VERSION ""

NS_ :

BS_:

BU_: Vector__XXX

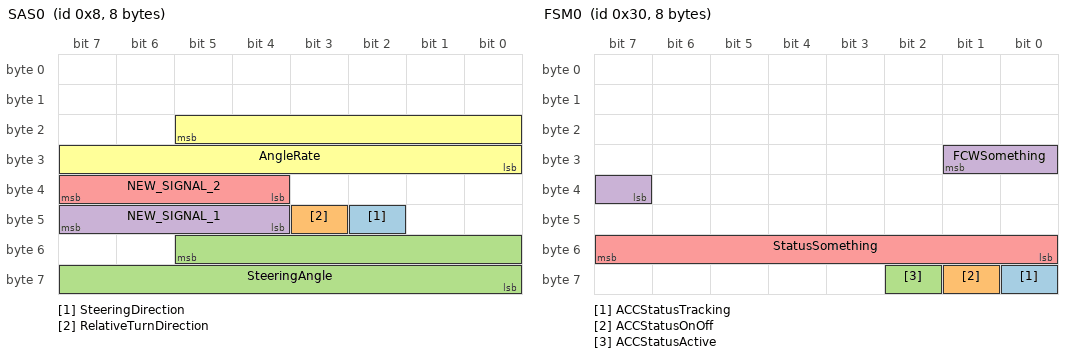
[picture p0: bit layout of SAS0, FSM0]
BO_ 8 SAS0: 8 Vector__XXX
SG_ SteeringDirection : 42|1@0+ (1,0) [0|1] "" Vector__XXX
SG_ RelativeTurnDirection : 43|1@0+ (1,0) [0|1] "" Vector__XXX
SG_ SteeringAngle : 53|14@0+ (0.04395,0) [0|720.03285] "degrees" Vector__XXX
SG_ NEW_SIGNAL_1 : 47|4@0+ (1,0) [0|15] "" Vector__XXX
SG_ NEW_SIGNAL_2 : 39|4@0+ (1,0) [0|15] "" Vector__XXX
SG_ AngleRate : 21|14@0+ (0.075,0) [0|1228.725] "deg/S" Vector__XXX

BO_ 16 CCButtons: 8 Vector__XXX
SG_ byte0 : 7|8@0+ (1,0) [0|255] "" Vector__XXX
SG_ byte1 : 15|8@0+ (1,0) [0|255] "" Vector__XXX
SG_ byte2 : 23|8@0+ (1,0) [0|255] "" Vector__XXX
SG_ byte3 : 31|8@0+ (1,0) [0|255] "" Vector__XXX
SG_ byte4 : 39|8@0+ (1,0) [0|255] "" Vector__XXX
SG_ byte6 : 55|5@0+ (1,0) [0|31] "" Vector__XXX
SG_ B7b0 : 56|1@0+ (1,0) [0|1] "" Vector__XXX
SG_ B7b1 : 57|1@0+ (1,0) [0|1] "" Vector__XXX
SG_ B7b6 : 62|1@0+ (1,0) [0|1] "" Vector__XXX
SG_ ACCOnOffBtn : 58|1@0+ (1,0) [0|1] "" Vector__XXX
SG_ ACCSetBtn : 63|1@0+ (1,0) [0|1] "" Vector__XXX
SG_ ACCStopBtn : 60|1@0+ (1,0) [0|1] "" Vector__XXX
SG_ ACCResumeBtn : 61|1@0+ (1,0) [0|1] "" Vector__XXX
SG_ ACCMinusBtn : 48|1@0+ (1,0) [0|1] "" Vector__XXX
SG_ TimeGapIncreaseBtn : 49|1@0+ (1,0) [0|1] "" Vector__XXX
SG_ TimeGapDecreaseBtn : 50|1@0+ (1,0) [0|1] "" Vector__XXX
SG_ byte5 : 47|8@0+ (1,0) [0|255] "" Vector__XXX
SG_ B7b3 : 59|1@0+ (1,0) [0|1] "" Vector__XXX

BO_ 48 FSM0: 8 Vector__XXX
SG_ ACCStatusTracking : 56|1@0+ (1,0) [0|1] "" Vector__XXX
SG_ ACCStatusOnOff : 57|1@0+ (1,0) [0|1] "" Vector__XXX
SG_ ACCStatusActive : 58|1@0+ (1,0) [0|1] "" Vector__XXX
SG_ FCWSomething : 25|3@0+ (1,0) [0|3] "" Vector__XXX
SG_ StatusSomething : 55|8@0+ (1,0) [0|255] "" Vector__XXX

BO_ 64 TCM0: 8 Vector__XXX
SG_ RPMSomething : 42|11@0+ (1,0) [0|2047] "" Vector__XXX
SG_ GearShifter : 46|2@0+ (1,0) [0|3] "" Vector__XXX

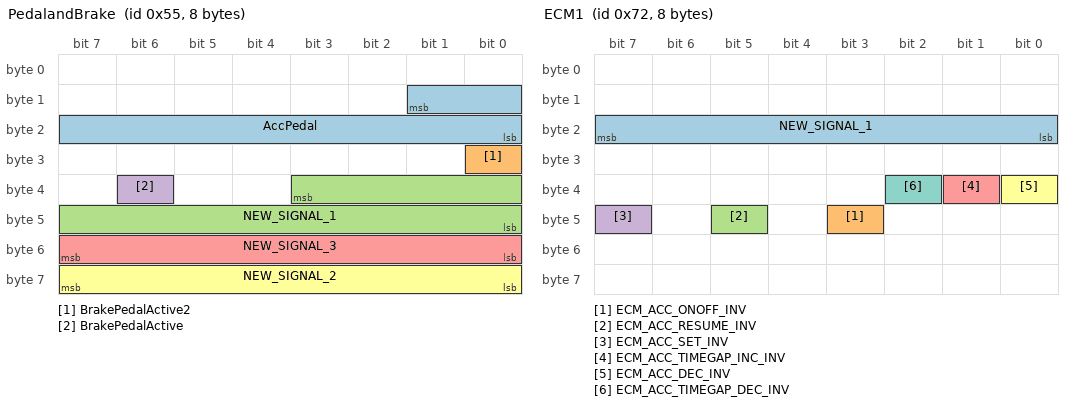
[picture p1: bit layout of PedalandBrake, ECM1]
BO_ 85 PedalandBrake: 8 Vector__XXX
SG_ AccPedal : 9|10@0+ (0.1,0) [0|102.3] "%" Vector__XXX
SG_ BrakePedalActive2 : 24|1@0+ (1,0) [0|1] "" Vector__XXX
SG_ NEW_SIGNAL_1 : 35|12@0+ (1,0) [0|4095] "" Vector__XXX
SG_ BrakePedalActive : 38|1@0+ (1,0) [0|1] "" Vector__XXX
SG_ NEW_SIGNAL_3 : 55|8@0+ (1,0) [0|255] "" Vector__XXX
SG_ NEW_SIGNAL_2 : 63|8@0+ (1,0) [0|255] "" Vector__XXX

BO_ 101 EngineInfo: 8 Vector__XXX
SG_ NEW_SIGNAL_1 : 17|10@0+ (1,-512) [0|511] "" Vector__XXX
SG_ EngineSpeed : 52|13@0+ (1,0) [0|1023] "" Vector__XXX

BO_ 112 NEW_MSG_4: 8 Vector__XXX
SG_ NEW_SIGNAL_1 : 39|8@0+ (1,0) [0|255] "" Vector__XXX

BO_ 114 ECM1: 8 Vector__XXX
SG_ NEW_SIGNAL_1 : 23|8@0+ (1,0) [0|255] "" Vector__XXX
SG_ ECM_ACC_ONOFF_INV : 43|1@0+ (1,0) [0|1] "" Vector__XXX
SG_ ECM_ACC_RESUME_INV : 45|1@0+ (1,0) [0|1] "" Vector__XXX
SG_ ECM_ACC_SET_INV : 47|1@0+ (1,0) [0|1] "" Vector__XXX
SG_ ECM_ACC_TIMEGAP_INC_INV : 33|1@0+ (1,0) [0|1] "" Vector__XXX
SG_ ECM_ACC_DEC_INV : 32|1@0+ (1,0) [0|1] "" Vector__XXX
SG_ ECM_ACC_TIMEGAP_DEC_INV : 34|1@0+ (1,0) [0|1] "" Vector__XXX

BO_ 117 ECM1_2: 8 Vector__XXX

BO_ 128 NEW_MSG_5: 8 Vector__XXX
SG_ NEW_SIGNAL_2 : 26|11@0+ (1,0) [0|2047] "" Vector__XXX
SG_ NEW_SIGNAL_1 : 52|13@0+ (1,0) [0|8191] "" Vector__XXX

BO_ 176 ECM2: 8 Vector__XXX
SG_ NEW_SIGNAL_1 : 50|11@0+ (1,0) [0|2047] "" Vector__XXX
SG_ NEW_SIGNAL_2 : 47|8@0+ (1,0) [0|63] "" Vector__XXX

BO_ 192 Gear: 8 Vector__XXX
SG_ TransmissionGear : 36|3@0+ (1,1) [1|7] "" Vector__XXX

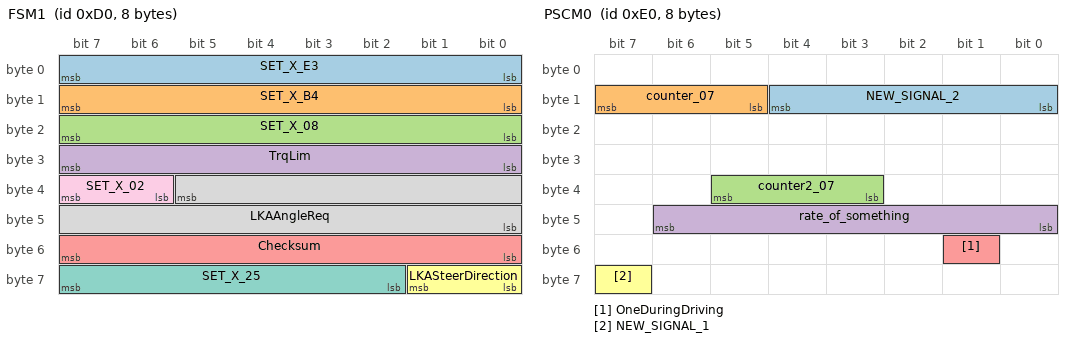
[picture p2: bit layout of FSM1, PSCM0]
BO_ 208 FSM1: 8 Vector__XXX
SG_ SET_X_E3 : 7|8@0+ (1,0) [0|255] "" Vector__XXX
SG_ SET_X_B4 : 15|8@0+ (1,0) [0|255] "" Vector__XXX
SG_ SET_X_08 : 23|8@0+ (1,0) [0|255] "" Vector__XXX
SG_ TrqLim : 31|8@0+ (1,-128) [0|127] "" Vector__XXX
SG_ Checksum : 55|8@0+ (1,0) [0|255] "" Vector__XXX
SG_ LKASteerDirection : 57|2@0+ (1,0) [0|2] "" Vector__XXX
SG_ SET_X_25 : 63|6@0+ (1,0) [0|63] "" Vector__XXX
SG_ LKAAngleReq : 37|14@0+ (0.04395,-360.0384) [-360.0384|359.99445] "degrees" Vector__XXX
SG_ SET_X_02 : 39|2@0+ (1,0) [0|3] "" Vector__XXX

BO_ 224 PSCM0: 8 Vector__XXX
SG_ NEW_SIGNAL_2 : 12|5@0+ (1,0) [0|31] "" Vector__XXX
SG_ counter_07 : 15|3@0+ (1,0) [0|7] "" Vector__XXX
SG_ counter2_07 : 37|3@0+ (1,0) [0|7] "" Vector__XXX
SG_ rate_of_something : 46|7@0+ (1,0) [0|62] "" Vector__XXX
SG_ OneDuringDriving : 49|1@0+ (1,0) [0|1] "" Vector__XXX
SG_ NEW_SIGNAL_1 : 63|1@0+ (1,0) [0|1] "" Vector__XXX

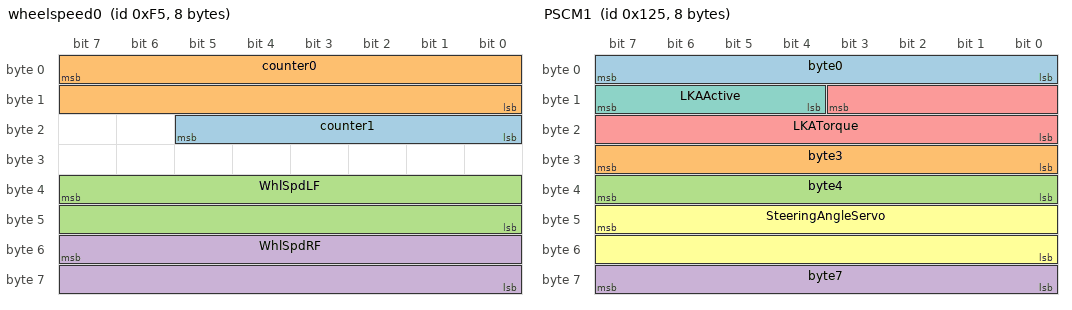
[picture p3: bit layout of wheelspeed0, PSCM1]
BO_ 245 wheelspeed0: 8 Vector__XXX
SG_ counter1 : 21|6@0+ (1,0) [0|63] "" Vector__XXX
SG_ counter0 : 7|16@0+ (1,0) [0|65535] "" Vector__XXX
SG_ WhlSpdLF : 39|16@0+ (1,0) [0|65535] "" Vector__XXX
SG_ WhlSpdRF : 55|16@0+ (1,0) [0|65535] "" Vector__XXX

BO_ 272 SpeedSignal0: 8 Vector__XXX
SG_ VehicleSpeedSignal : 55|16@0+ (0.01,0) [0|655.35] "" Vector__XXX

BO_ 288 wheel_speed1: 8 Vector__XXX
SG_ WhlSpdLR : 39|16@0+ (1,0) [0|65535] "" Vector__XXX
SG_ WhlSpdRR : 55|16@0+ (1,0) [0|65535] "" Vector__XXX

BO_ 293 PSCM1: 8 Vector__XXX
SG_ byte0 : 7|8@0+ (1,0) [0|255] "" Vector__XXX
SG_ byte3 : 31|8@0+ (1,0) [0|255] "" Vector__XXX
SG_ byte4 : 39|8@0+ (1,0) [0|255] "" Vector__XXX
SG_ byte7 : 63|8@0+ (1,0) [0|255] "" Vector__XXX
SG_ LKATorque : 11|12@0+ (1,-2000) [0|2095] "" Vector__XXX
SG_ SteeringAngleServo : 47|16@0+ (0.04395,-1440.1536) [0|1440.10965] "deg" Vector__XXX
SG_ LKAActive : 15|4@0+ (1,0) [0|15] "" Vector__XXX

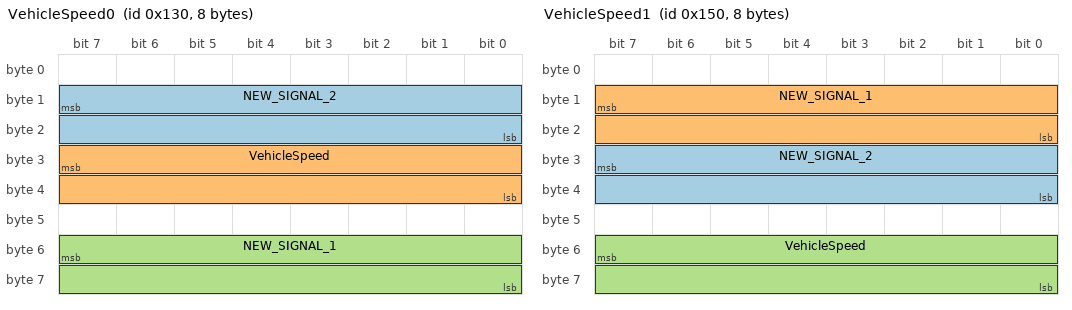
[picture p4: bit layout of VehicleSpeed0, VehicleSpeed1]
BO_ 304 VehicleSpeed0: 8 Vector__XXX
SG_ NEW_SIGNAL_2 : 15|16@0+ (1,0) [0|65535] "" Vector__XXX
SG_ VehicleSpeed : 31|16@0+ (0.01,0) [0|655.35] "km/h" Vector__XXX
SG_ NEW_SIGNAL_1 : 55|16@0+ (1,0) [0|65535] "" Vector__XXX

BO_ 325 ECM3: 8 Vector__XXX

BO_ 336 VehicleSpeed1: 8 Vector__XXX
SG_ NEW_SIGNAL_2 : 31|16@0+ (1,0) [0|65535] "" Vector__XXX
SG_ NEW_SIGNAL_1 : 15|16@0+ (1,0) [0|65535] "" Vector__XXX
SG_ VehicleSpeed : 55|16@0+ (0.01,0) [0|655.35] "" Vector__XXX

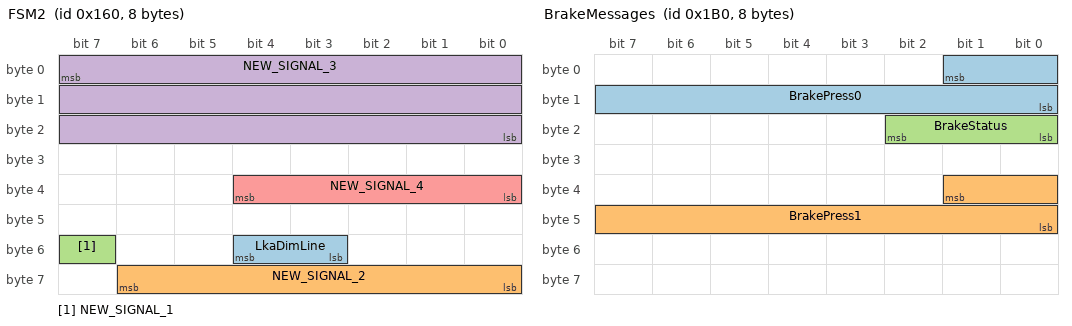
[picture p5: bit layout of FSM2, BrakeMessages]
BO_ 352 FSM2: 8 Vector__XXX
SG_ LkaDimLine : 51|2@1+ (1,0) [0|3] "" Vector__XXX
SG_ NEW_SIGNAL_2 : 56|7@1+ (1,0) [0|127] "" Vector__XXX
SG_ NEW_SIGNAL_1 : 55|1@0+ (1,0) [0|1] "" Vector__XXX
SG_ NEW_SIGNAL_3 : 7|24@0+ (1,0) [0|16777215] "" Vector__XXX
SG_ NEW_SIGNAL_4 : 36|5@0+ (1,0) [0|31] "" Vector__XXX

BO_ 432 BrakeMessages: 8 Vector__XXX
SG_ BrakePress0 : 1|10@0+ (1,0) [0|1023] "" Vector__XXX
SG_ BrakePress1 : 33|10@0+ (1,0) [0|1023] "" Vector__XXX
SG_ BrakeStatus : 18|3@0+ (1,0) [0|7] "" Vector__XXX

BO_ 464 DIM0: 8 Vector__XXX

BO_ 480 BCM0: 8 Vector__XXX

BO_ 528 CEM0: 8 Vector__XXX

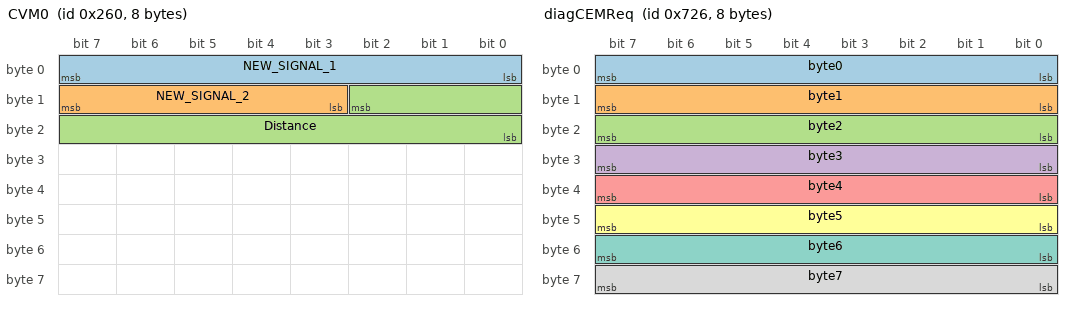
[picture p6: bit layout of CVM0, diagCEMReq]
BO_ 608 CVM0: 8 Vector__XXX
SG_ NEW_SIGNAL_1 : 7|8@0+ (1,0) [0|255] "" Vector__XXX
SG_ NEW_SIGNAL_2 : 15|5@0+ (1,0) [0|31] "" Vector__XXX
SG_ Distance : 10|11@0+ (1,0) [0|2047] "" Vector__XXX

BO_ 624 FSM3: 8 Vector__XXX
SG_ NEW_SIGNAL_1 : 23|8@0+ (1,0) [0|255] "" Vector__XXX

BO_ 640 FSM4: 8 Vector__XXX
SG_ SpeedTarget : 47|8@0+ (1,0) [0|255] "" Vector__XXX
SG_ NEW_SIGNAL_1 : 49|10@0+ (1,0) [0|255] "" Vector__XXX

BO_ 648 SRS0: 8 Vector__XXX

BO_ 652 ECM4: 8 Vector__XXX

BO_ 656 ECM5: 8 Vector__XXX

BO_ 657 ECM6: 8 Vector__XXX

BO_ 681 MiscCarInfo: 8 Vector__XXX
SG_ TurnSignal : 1|2@0+ (1,0) [0|3] "" Vector__XXX
SG_ HighBeamOn : 52|1@0+ (1,0) [0|1] "" Vector__XXX

BO_ 693 ECM7: 8 Vector__XXX

BO_ 709 ACC: 8 Vector__XXX
SG_ SpeedTargetACC : 0|9@0+ (0.5,0) [0|255.5] "" Vector__XXX

BO_ 853 FSM5: 8 Vector__XXX
SG_ TargetSpeedOdo : 23|8@0+ (1,0) [0|63] "kph" Vector__XXX
SG_ SpeedSign : 36|5@0+ (5,0) [0|32] "" Vector__XXX
SG_ TextUnderSign : 37|1@0+ (1,0) [0|1] "" Vector__XXX
SG_ NEW_SIGNAL_6 : 39|3@0+ (1,0) [0|3] "" Vector__XXX
SG_ NEW_SIGNAL_5 : 47|8@0+ (1,0) [0|255] "" Vector__XXX
SG_ NEW_SIGNAL_3 : 31|8@0+ (1,0) [0|255] "" Vector__XXX
SG_ LaneMarkingsOdo : 15|4@0+ (1,0) [0|7] "" Vector__XXX
SG_ NEW_SIGNAL_2 : 11|4@0+ (1,0) [0|15] "" Vector__XXX
SG_ NEW_SIGNAL_1 : 7|8@0+ (1,0) [0|255] "" Vector__XXX
SG_ NEW_SIGNAL_4 : 55|16@0+ (1,0) [0|65535] "" Vector__XXX

BO_ 864 CEM1: 8 Vector__XXX

BO_ 912 DIM1: 8 Vector__XXX

BO_ 968 SRS1: 8 Vector__XXX
SG_ PassengerSeatBelt : 22|1@0+ (1,0) [0|1] "" Vector__XXX
SG_ DriverSeatBelt : 19|1@0+ (1,0) [0|1] "" Vector__XXX

BO_ 1029 CEMBCM0: 8 Vector__XXX

BO_ 1344 NEW_MSG_1: 8 Vector__XXX
SG_ NEW_SIGNAL_1 : 4|13@0+ (1,0) [0|8191] "" Vector__XXX

BO_ 1830 diagCEMReq: 8 Vector__XXX
SG_ byte0 : 7|8@0+ (1,0) [0|255] "" Vector__XXX
SG_ byte1 : 15|8@0+ (1,0) [0|255] "" Vector__XXX
SG_ byte2 : 23|8@0+ (1,0) [0|255] "" Vector__XXX
SG_ byte3 : 31|8@0+ (1,0) [0|255] "" Vector__XXX
SG_ byte4 : 39|8@0+ (1,0) [0|255] "" Vector__XXX
SG_ byte5 : 47|8@0+ (1,0) [0|255] "" Vector__XXX
SG_ byte6 : 55|8@0+ (1,0) [0|255] "" Vector__XXX
SG_ byte7 : 63|8@0+ (1,0) [0|255] "" Vector__XXX

BO_ 1838 diagCEMResp: 8 Vector__XXX
SG_ byte03 : 7|32@0+ (1,0) [0|4294967295] "" Vector__XXX
SG_ byte47 : 39|32@0+ (1,0) [0|4294967295] "" Vector__XXX

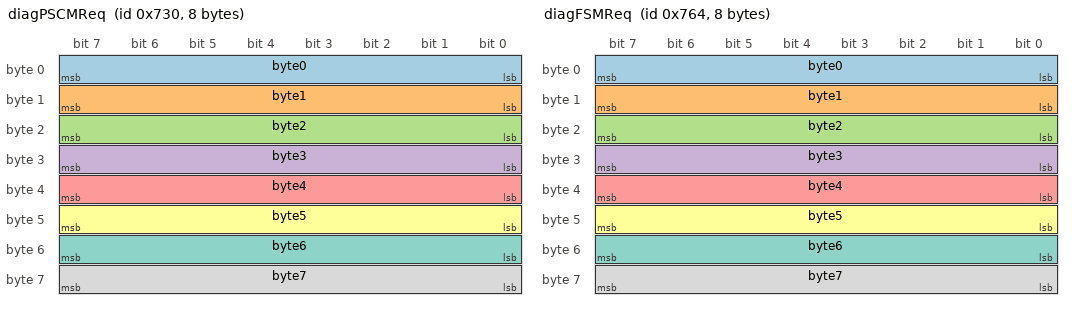
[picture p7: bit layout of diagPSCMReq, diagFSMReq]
BO_ 1840 diagPSCMReq: 8 Vector__XXX
SG_ byte0 : 7|8@0+ (1,0) [0|255] "" Vector__XXX
SG_ byte1 : 15|8@0+ (1,0) [0|255] "" Vector__XXX
SG_ byte2 : 23|8@0+ (1,0) [0|255] "" Vector__XXX
SG_ byte3 : 31|8@0+ (1,0) [0|255] "" Vector__XXX
SG_ byte4 : 39|8@0+ (1,0) [0|255] "" Vector__XXX
SG_ byte5 : 47|8@0+ (1,0) [0|255] "" Vector__XXX
SG_ byte6 : 55|8@0+ (1,0) [0|255] "" Vector__XXX
SG_ byte7 : 63|8@0+ (1,0) [0|255] "" Vector__XXX

BO_ 1848 diagPSCMResp: 8 Vector__XXX
SG_ byte03 : 7|32@0+ (1,0) [0|4294967295] "" Vector__XXX
SG_ byte47 : 39|32@0+ (1,0) [0|4294967295] "" Vector__XXX

BO_ 1892 diagFSMReq: 8 Vector__XXX
SG_ byte0 : 7|8@0+ (1,0) [0|255] "" Vector__XXX
SG_ byte1 : 15|8@0+ (1,0) [0|255] "" Vector__XXX
SG_ byte2 : 23|8@0+ (1,0) [0|255] "" Vector__XXX
SG_ byte3 : 31|8@0+ (1,0) [0|255] "" Vector__XXX
SG_ byte4 : 39|8@0+ (1,0) [0|255] "" Vector__XXX
SG_ byte5 : 47|8@0+ (1,0) [0|255] "" Vector__XXX
SG_ byte6 : 55|8@0+ (1,0) [0|255] "" Vector__XXX
SG_ byte7 : 63|8@0+ (1,0) [0|255] "" Vector__XXX

BO_ 1900 diagFSMResp: 8 Vector__XXX
SG_ byte03 : 7|32@0+ (1,0) [0|4294967295] "" Vector__XXX
SG_ byte47 : 39|32@0+ (1,0) [0|4294967295] "" Vector__XXX

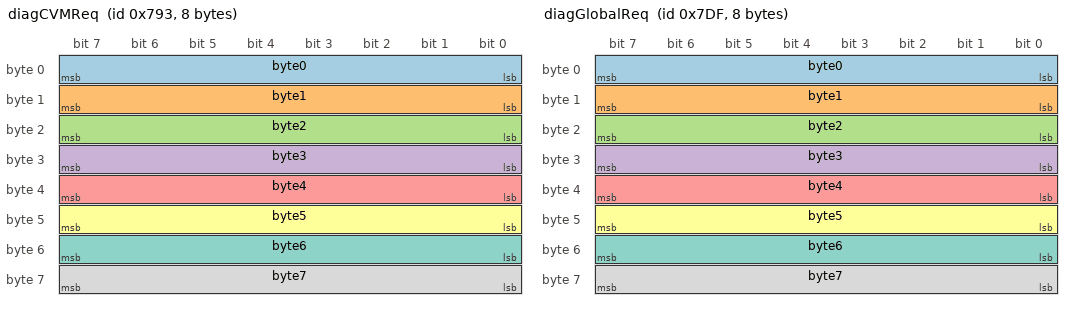
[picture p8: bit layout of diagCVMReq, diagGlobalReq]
BO_ 1939 diagCVMReq: 8 Vector__XXX
SG_ byte0 : 7|8@0+ (1,0) [0|255] "" Vector__XXX
SG_ byte1 : 15|8@0+ (1,0) [0|255] "" Vector__XXX
SG_ byte2 : 23|8@0+ (1,0) [0|255] "" Vector__XXX
SG_ byte3 : 31|8@0+ (1,0) [0|255] "" Vector__XXX
SG_ byte4 : 39|8@0+ (1,0) [0|255] "" Vector__XXX
SG_ byte5 : 47|8@0+ (1,0) [0|255] "" Vector__XXX
SG_ byte6 : 55|8@0+ (1,0) [0|255] "" Vector__XXX
SG_ byte7 : 63|8@0+ (1,0) [0|255] "" Vector__XXX

BO_ 1947 diagCVMResp: 8 Vector__XXX
SG_ byte03 : 7|32@0+ (1,0) [0|4294967295] "" Vector__XXX
SG_ byte47 : 39|32@0+ (1,0) [0|4294967295] "" Vector__XXX

BO_ 2015 diagGlobalReq: 8 Vector__XXX
SG_ byte0 : 7|8@0+ (1,0) [0|255] "" Vector__XXX
SG_ byte1 : 15|8@0+ (1,0) [0|255] "" Vector__XXX
SG_ byte2 : 23|8@0+ (1,0) [0|255] "" Vector__XXX
SG_ byte3 : 31|8@0+ (1,0) [0|255] "" Vector__XXX
SG_ byte4 : 39|8@0+ (1,0) [0|255] "" Vector__XXX
SG_ byte5 : 47|8@0+ (1,0) [0|255] "" Vector__XXX
SG_ byte6 : 55|8@0+ (1,0) [0|255] "" Vector__XXX
SG_ byte7 : 63|8@0+ (1,0) [0|255] "" Vector__XXX

CM_ SG_ 8 SteeringDirection "1=Right turn, 0=Left turn. Steering wheel pointing left or right from center (0 deg).";
CM_ SG_ 8 RelativeTurnDirection "1=Right turn, 0=Left turn. Steering wheel currently turning the way.";
CM_ SG_ 16 ACCOnOffBtn "Cruise control on/off button pressed";
CM_ SG_ 16 ACCSetBtn "Acc Set button (+) pressed";
CM_ SG_ 16 ACCStopBtn "ACC Stop button pressed";
CM_ SG_ 16 ACCResumeBtn "ACC Resume button pressed";
CM_ SG_ 16 ACCMinusBtn "ACC Minus (-) button pressed";
CM_ SG_ 16 TimeGapIncreaseBtn "Increase the time gap on ACC";
CM_ SG_ 16 TimeGapDecreaseBtn "Decrease the time gap on ACC";
CM_ SG_ 48 ACCStatusTracking "ACC Tracking vehicle, distance control.";
CM_ SG_ 48 ACCStatusOnOff "Turns one after pressing on/off button on steering wheeel";
CM_ SG_ 48 ACCStatusActive "ACC Active";
CM_ SG_ 48 FCWSomething "All bit set during fcw";
CM_ SG_ 48 StatusSomething "Some status changes when zeroing DTCs";
CM_ SG_ 64 RPMSomething "TransmissionOutput?";
CM_ SG_ 64 GearShifter "P=0, R=1, N=2, D=3";
CM_ SG_ 85 BrakePedalActive2 "Active during braking";
CM_ SG_ 85 NEW_SIGNAL_1 "Not yet figured out.";
CM_ SG_ 85 BrakePedalActive "Brake pedal pushed";
CM_ SG_ 101 NEW_SIGNAL_1 "Rate of something?";
CM_ SG_ 114 NEW_SIGNAL_1 "Jumped from 0 -> 120 during start. Makes triangle from time to time";
CM_ SG_ 192 TransmissionGear "0 = 1st gear, 1= 2nd gear...";
CM_ SG_ 208 TrqLim "Used in checksum calculation, Limit directional torque based on the number.";
CM_ SG_ 208 Checksum "Checksum calculated as a one-complement addition of LKAAngleRequest+LKADirection+Unkown, Zeros used to pad missing bits.";
CM_ SG_ 208 SET_X_02 "Bit 0 = Vibrate steering wheel., Bit 1 = Heartbeat";
CM_ SG_ 224 rate_of_something "Seems to be some kind of torque rather than rate.";
CM_ SG_ 224 OneDuringDriving "Set to 1 when vehicle is rolling.";
CM_ SG_ 245 counter0 "Speed based counter";
CM_ SG_ 245 WhlSpdLF "Wheel speed left front";
CM_ SG_ 245 WhlSpdRF "Wheel speed right front";
CM_ SG_ 272 VehicleSpeedSignal "km/h";
CM_ SG_ 288 WhlSpdLR "Wheel speed left rear";
CM_ SG_ 288 WhlSpdRR "Wheel speed right rear";
CM_ SG_ 293 byte7 "Bit0=0 when gearshift in park, else 1";
CM_ SG_ 293 LKAActive "Bit0=0 when gear in park otherwise =1, Bit1=1 when LKA Active, 0 when not active. Bit2=? Bit3=?";
CM_ SG_ 352 LkaDimLine "Not true, but follows lka steer direction.";
CM_ SG_ 352 NEW_SIGNAL_1 "Turned one. Got LKA service needed can this be the one?";
CM_ SG_ 432 BrakePress0 "Brake being pressed";
CM_ SG_ 432 BrakePress1 "Brake being pressed";
CM_ SG_ 432 BrakeStatus "ACC brake?";
CM_ SG_ 608 NEW_SIGNAL_1 "Status?";
CM_ SG_ 608 NEW_SIGNAL_2 "Classification of object?";
CM_ SG_ 608 Distance "Distance to object in front.";
CM_ SG_ 640 SpeedTarget "SpeedTarget ACC (noisy bf starting acc Jumps from 0->252->0)";
CM_ SG_ 681 TurnSignal "0 = Nothing, 1= Left, 3=Right";
CM_ SG_ 681 HighBeamOn "1=HighBeam On, 0=HighBeam Off";
CM_ SG_ 709 SpeedTargetACC "SpeedTargetACC";
CM_ SG_ 853 TargetSpeedOdo "Probably target speed odo";
CM_ SG_ 853 LaneMarkingsOdo "Bit 3=Left lane, Bit 2=Right lane, Bit 1=LKA on?, Bit 0=?";
CM_ SG_ 968 PassengerSeatBelt "1 = Seatbalt latched";
CM_ SG_ 968 DriverSeatBelt "1=Seatbelt latched";

BA_DEF_  "BusType" STRING ;
BA_DEF_ SG_  "GenSigStartValue" FLOAT -3.4E+038 3.4E+038;

BA_DEF_DEF_  "BusType" "CAN";
BA_DEF_DEF_  "GenSigStartValue" 0;

BA_ "GenSigStartValue" SG_ 192 TransmissionGear 1;
VAL_ 64 GearShifter 0 "P" 1 "R" 2 "N" 3 "D";
